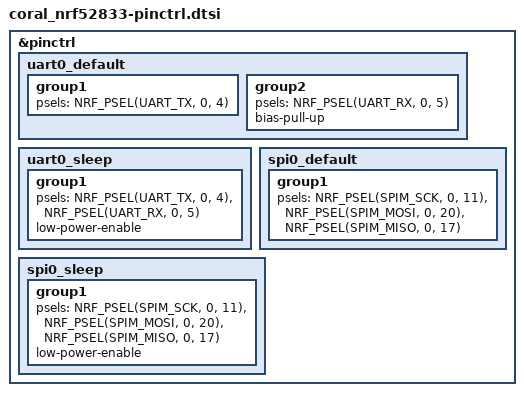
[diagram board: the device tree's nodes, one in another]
&pinctrl {
	uart0_default: uart0_default {
		group1 {
			psels = <NRF_PSEL(UART_TX, 0, 4)>;
		};

		group2 {
			psels = <NRF_PSEL(UART_RX, 0, 5)>;
			bias-pull-up;
		};
	};

	uart0_sleep: uart0_sleep {
		group1 {
			psels = <NRF_PSEL(UART_TX, 0, 4)>,
				<NRF_PSEL(UART_RX, 0, 5)>;
			low-power-enable;
		};
	};

	spi0_default: spi0_default {
		group1 {
			psels = <NRF_PSEL(SPIM_SCK, 0, 11)>,
				<NRF_PSEL(SPIM_MOSI, 0, 20)>,
				<NRF_PSEL(SPIM_MISO, 0, 17)>;
		};
	};

	spi0_sleep: spi0_sleep {
		group1 {
			psels = <NRF_PSEL(SPIM_SCK, 0, 11)>,
				<NRF_PSEL(SPIM_MOSI, 0, 20)>,
				<NRF_PSEL(SPIM_MISO, 0, 17)>;
			low-power-enable;
		};
	};
};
